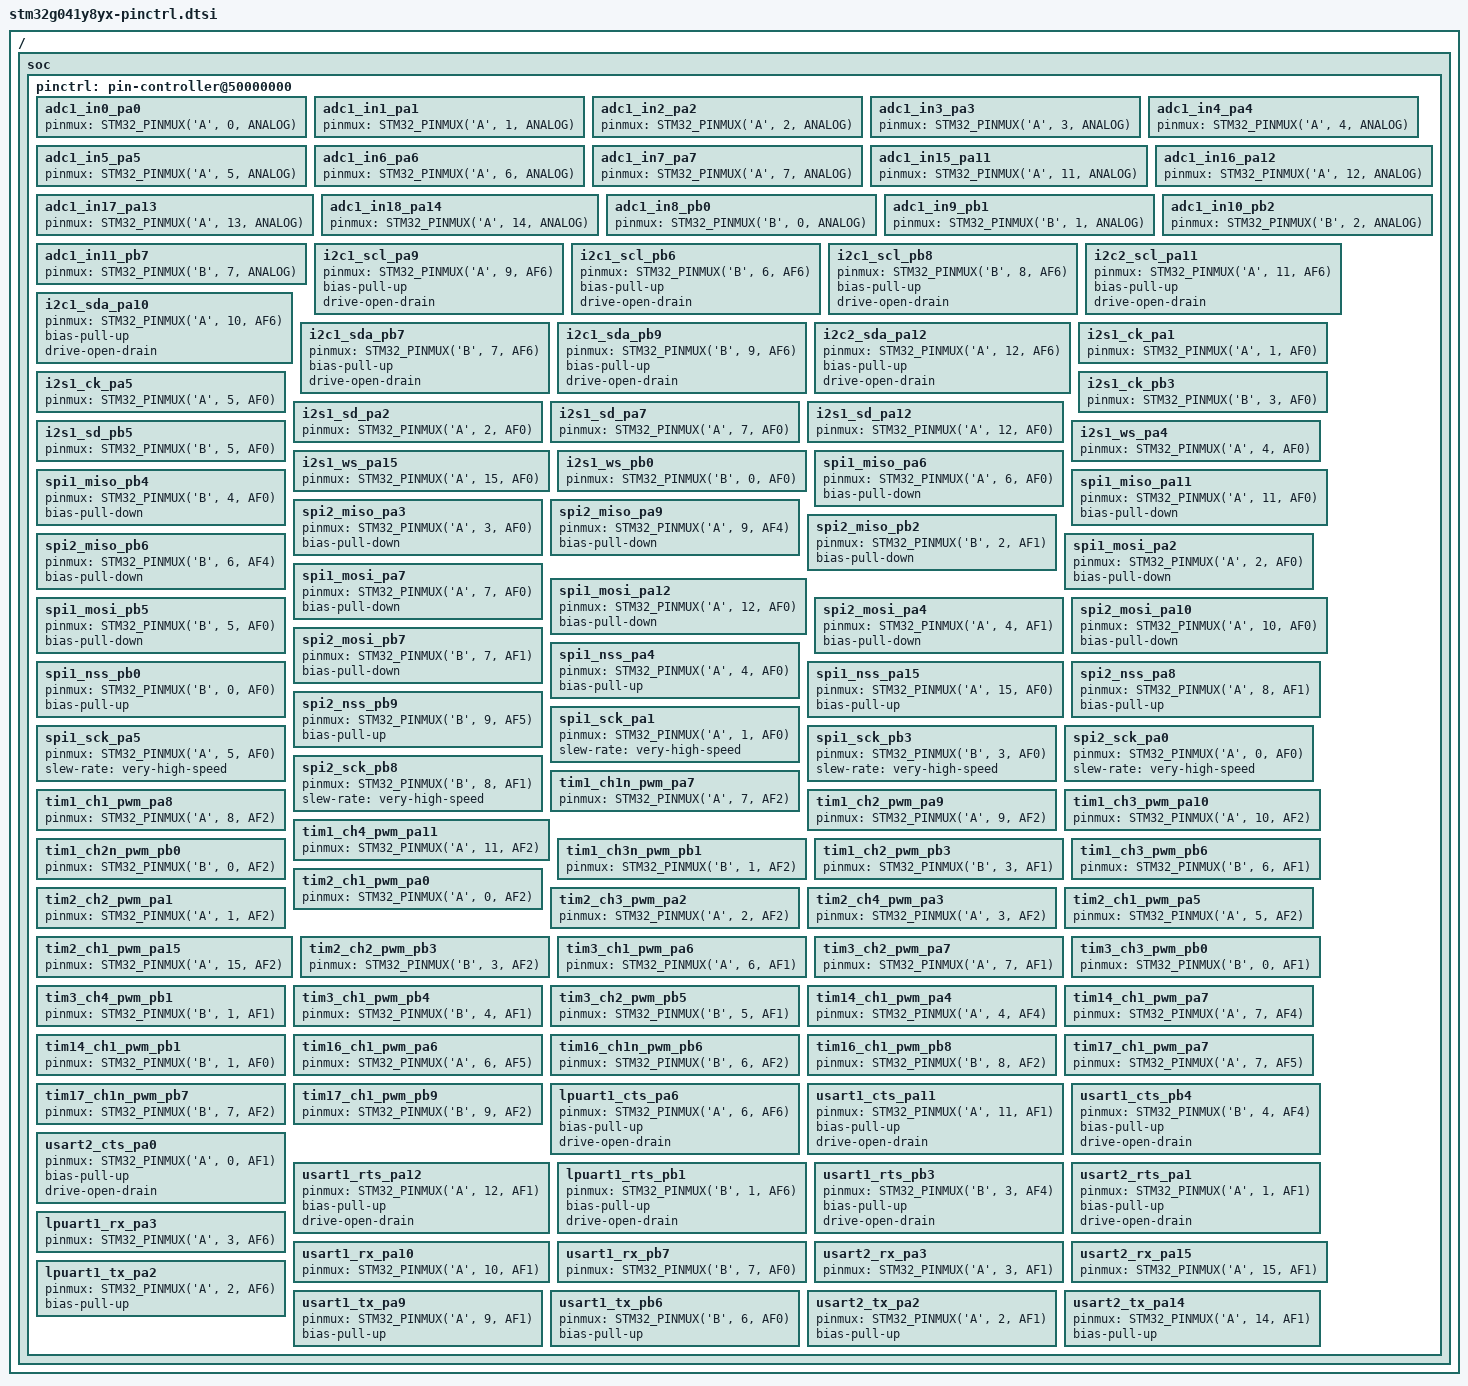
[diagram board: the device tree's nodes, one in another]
/*
 * NOTE: Autogenerated file using genpinctrl.py
 *
 * SPDX-License-Identifier: Apache-2.0
 */

#include <dt-bindings/pinctrl/stm32-pinctrl.h>

/ {
	soc {
		pinctrl: pin-controller@50000000 {

			/* ADC_IN / ADC_INN / ADC_INP */

			adc1_in0_pa0: adc1_in0_pa0 {
				pinmux = <STM32_PINMUX('A', 0, ANALOG)>;
			};

			adc1_in1_pa1: adc1_in1_pa1 {
				pinmux = <STM32_PINMUX('A', 1, ANALOG)>;
			};

			adc1_in2_pa2: adc1_in2_pa2 {
				pinmux = <STM32_PINMUX('A', 2, ANALOG)>;
			};

			adc1_in3_pa3: adc1_in3_pa3 {
				pinmux = <STM32_PINMUX('A', 3, ANALOG)>;
			};

			adc1_in4_pa4: adc1_in4_pa4 {
				pinmux = <STM32_PINMUX('A', 4, ANALOG)>;
			};

			adc1_in5_pa5: adc1_in5_pa5 {
				pinmux = <STM32_PINMUX('A', 5, ANALOG)>;
			};

			adc1_in6_pa6: adc1_in6_pa6 {
				pinmux = <STM32_PINMUX('A', 6, ANALOG)>;
			};

			adc1_in7_pa7: adc1_in7_pa7 {
				pinmux = <STM32_PINMUX('A', 7, ANALOG)>;
			};

			adc1_in15_pa11: adc1_in15_pa11 {
				pinmux = <STM32_PINMUX('A', 11, ANALOG)>;
			};

			adc1_in16_pa12: adc1_in16_pa12 {
				pinmux = <STM32_PINMUX('A', 12, ANALOG)>;
			};

			adc1_in17_pa13: adc1_in17_pa13 {
				pinmux = <STM32_PINMUX('A', 13, ANALOG)>;
			};

			adc1_in18_pa14: adc1_in18_pa14 {
				pinmux = <STM32_PINMUX('A', 14, ANALOG)>;
			};

			adc1_in8_pb0: adc1_in8_pb0 {
				pinmux = <STM32_PINMUX('B', 0, ANALOG)>;
			};

			adc1_in9_pb1: adc1_in9_pb1 {
				pinmux = <STM32_PINMUX('B', 1, ANALOG)>;
			};

			adc1_in10_pb2: adc1_in10_pb2 {
				pinmux = <STM32_PINMUX('B', 2, ANALOG)>;
			};

			adc1_in11_pb7: adc1_in11_pb7 {
				pinmux = <STM32_PINMUX('B', 7, ANALOG)>;
			};

			/* I2C_SCL */

			i2c1_scl_pa9: i2c1_scl_pa9 {
				pinmux = <STM32_PINMUX('A', 9, AF6)>;
				bias-pull-up;
				drive-open-drain;
			};

			i2c1_scl_pb6: i2c1_scl_pb6 {
				pinmux = <STM32_PINMUX('B', 6, AF6)>;
				bias-pull-up;
				drive-open-drain;
			};

			i2c1_scl_pb8: i2c1_scl_pb8 {
				pinmux = <STM32_PINMUX('B', 8, AF6)>;
				bias-pull-up;
				drive-open-drain;
			};

			i2c2_scl_pa11: i2c2_scl_pa11 {
				pinmux = <STM32_PINMUX('A', 11, AF6)>;
				bias-pull-up;
				drive-open-drain;
			};

			/* I2C_SDA */

			i2c1_sda_pa10: i2c1_sda_pa10 {
				pinmux = <STM32_PINMUX('A', 10, AF6)>;
				bias-pull-up;
				drive-open-drain;
			};

			i2c1_sda_pb7: i2c1_sda_pb7 {
				pinmux = <STM32_PINMUX('B', 7, AF6)>;
				bias-pull-up;
				drive-open-drain;
			};

			i2c1_sda_pb9: i2c1_sda_pb9 {
				pinmux = <STM32_PINMUX('B', 9, AF6)>;
				bias-pull-up;
				drive-open-drain;
			};

			i2c2_sda_pa12: i2c2_sda_pa12 {
				pinmux = <STM32_PINMUX('A', 12, AF6)>;
				bias-pull-up;
				drive-open-drain;
			};

			/* I2S_CK */

			i2s1_ck_pa1: i2s1_ck_pa1 {
				pinmux = <STM32_PINMUX('A', 1, AF0)>;
			};

			i2s1_ck_pa5: i2s1_ck_pa5 {
				pinmux = <STM32_PINMUX('A', 5, AF0)>;
			};

			i2s1_ck_pb3: i2s1_ck_pb3 {
				pinmux = <STM32_PINMUX('B', 3, AF0)>;
			};

			/* I2S_SD */

			i2s1_sd_pa2: i2s1_sd_pa2 {
				pinmux = <STM32_PINMUX('A', 2, AF0)>;
			};

			i2s1_sd_pa7: i2s1_sd_pa7 {
				pinmux = <STM32_PINMUX('A', 7, AF0)>;
			};

			i2s1_sd_pa12: i2s1_sd_pa12 {
				pinmux = <STM32_PINMUX('A', 12, AF0)>;
			};

			i2s1_sd_pb5: i2s1_sd_pb5 {
				pinmux = <STM32_PINMUX('B', 5, AF0)>;
			};

			/* I2S_WS */

			i2s1_ws_pa4: i2s1_ws_pa4 {
				pinmux = <STM32_PINMUX('A', 4, AF0)>;
			};

			i2s1_ws_pa15: i2s1_ws_pa15 {
				pinmux = <STM32_PINMUX('A', 15, AF0)>;
			};

			i2s1_ws_pb0: i2s1_ws_pb0 {
				pinmux = <STM32_PINMUX('B', 0, AF0)>;
			};

			/* SPI_MISO */

			spi1_miso_pa6: spi1_miso_pa6 {
				pinmux = <STM32_PINMUX('A', 6, AF0)>;
				bias-pull-down;
			};

			spi1_miso_pa11: spi1_miso_pa11 {
				pinmux = <STM32_PINMUX('A', 11, AF0)>;
				bias-pull-down;
			};

			spi1_miso_pb4: spi1_miso_pb4 {
				pinmux = <STM32_PINMUX('B', 4, AF0)>;
				bias-pull-down;
			};

			spi2_miso_pa3: spi2_miso_pa3 {
				pinmux = <STM32_PINMUX('A', 3, AF0)>;
				bias-pull-down;
			};

			spi2_miso_pa9: spi2_miso_pa9 {
				pinmux = <STM32_PINMUX('A', 9, AF4)>;
				bias-pull-down;
			};

			spi2_miso_pb2: spi2_miso_pb2 {
				pinmux = <STM32_PINMUX('B', 2, AF1)>;
				bias-pull-down;
			};

			spi2_miso_pb6: spi2_miso_pb6 {
				pinmux = <STM32_PINMUX('B', 6, AF4)>;
				bias-pull-down;
			};

			/* SPI_MOSI */

			spi1_mosi_pa2: spi1_mosi_pa2 {
				pinmux = <STM32_PINMUX('A', 2, AF0)>;
				bias-pull-down;
			};

			spi1_mosi_pa7: spi1_mosi_pa7 {
				pinmux = <STM32_PINMUX('A', 7, AF0)>;
				bias-pull-down;
			};

			spi1_mosi_pa12: spi1_mosi_pa12 {
				pinmux = <STM32_PINMUX('A', 12, AF0)>;
				bias-pull-down;
			};

			spi1_mosi_pb5: spi1_mosi_pb5 {
				pinmux = <STM32_PINMUX('B', 5, AF0)>;
				bias-pull-down;
			};

			spi2_mosi_pa4: spi2_mosi_pa4 {
				pinmux = <STM32_PINMUX('A', 4, AF1)>;
				bias-pull-down;
			};

			spi2_mosi_pa10: spi2_mosi_pa10 {
				pinmux = <STM32_PINMUX('A', 10, AF0)>;
				bias-pull-down;
			};

			spi2_mosi_pb7: spi2_mosi_pb7 {
				pinmux = <STM32_PINMUX('B', 7, AF1)>;
				bias-pull-down;
			};

			/* SPI_NSS */

			spi1_nss_pa4: spi1_nss_pa4 {
				pinmux = <STM32_PINMUX('A', 4, AF0)>;
				bias-pull-up;
			};

			spi1_nss_pa15: spi1_nss_pa15 {
				pinmux = <STM32_PINMUX('A', 15, AF0)>;
				bias-pull-up;
			};

			spi1_nss_pb0: spi1_nss_pb0 {
				pinmux = <STM32_PINMUX('B', 0, AF0)>;
				bias-pull-up;
			};

			spi2_nss_pa8: spi2_nss_pa8 {
				pinmux = <STM32_PINMUX('A', 8, AF1)>;
				bias-pull-up;
			};

			spi2_nss_pb9: spi2_nss_pb9 {
				pinmux = <STM32_PINMUX('B', 9, AF5)>;
				bias-pull-up;
			};

			/* SPI_SCK */

			spi1_sck_pa1: spi1_sck_pa1 {
				pinmux = <STM32_PINMUX('A', 1, AF0)>;
				slew-rate = "very-high-speed";
			};

			spi1_sck_pa5: spi1_sck_pa5 {
				pinmux = <STM32_PINMUX('A', 5, AF0)>;
				slew-rate = "very-high-speed";
			};

			spi1_sck_pb3: spi1_sck_pb3 {
				pinmux = <STM32_PINMUX('B', 3, AF0)>;
				slew-rate = "very-high-speed";
			};

			spi2_sck_pa0: spi2_sck_pa0 {
				pinmux = <STM32_PINMUX('A', 0, AF0)>;
				slew-rate = "very-high-speed";
			};

			spi2_sck_pb8: spi2_sck_pb8 {
				pinmux = <STM32_PINMUX('B', 8, AF1)>;
				slew-rate = "very-high-speed";
			};

			/* TIM_CH_PWM / TIM_CHN_PWM */

			tim1_ch1n_pwm_pa7: tim1_ch1n_pwm_pa7 {
				pinmux = <STM32_PINMUX('A', 7, AF2)>;
			};

			tim1_ch1_pwm_pa8: tim1_ch1_pwm_pa8 {
				pinmux = <STM32_PINMUX('A', 8, AF2)>;
			};

			tim1_ch2_pwm_pa9: tim1_ch2_pwm_pa9 {
				pinmux = <STM32_PINMUX('A', 9, AF2)>;
			};

			tim1_ch3_pwm_pa10: tim1_ch3_pwm_pa10 {
				pinmux = <STM32_PINMUX('A', 10, AF2)>;
			};

			tim1_ch4_pwm_pa11: tim1_ch4_pwm_pa11 {
				pinmux = <STM32_PINMUX('A', 11, AF2)>;
			};

			tim1_ch2n_pwm_pb0: tim1_ch2n_pwm_pb0 {
				pinmux = <STM32_PINMUX('B', 0, AF2)>;
			};

			tim1_ch3n_pwm_pb1: tim1_ch3n_pwm_pb1 {
				pinmux = <STM32_PINMUX('B', 1, AF2)>;
			};

			tim1_ch2_pwm_pb3: tim1_ch2_pwm_pb3 {
				pinmux = <STM32_PINMUX('B', 3, AF1)>;
			};

			tim1_ch3_pwm_pb6: tim1_ch3_pwm_pb6 {
				pinmux = <STM32_PINMUX('B', 6, AF1)>;
			};

			tim2_ch1_pwm_pa0: tim2_ch1_pwm_pa0 {
				pinmux = <STM32_PINMUX('A', 0, AF2)>;
			};

			tim2_ch2_pwm_pa1: tim2_ch2_pwm_pa1 {
				pinmux = <STM32_PINMUX('A', 1, AF2)>;
			};

			tim2_ch3_pwm_pa2: tim2_ch3_pwm_pa2 {
				pinmux = <STM32_PINMUX('A', 2, AF2)>;
			};

			tim2_ch4_pwm_pa3: tim2_ch4_pwm_pa3 {
				pinmux = <STM32_PINMUX('A', 3, AF2)>;
			};

			tim2_ch1_pwm_pa5: tim2_ch1_pwm_pa5 {
				pinmux = <STM32_PINMUX('A', 5, AF2)>;
			};

			tim2_ch1_pwm_pa15: tim2_ch1_pwm_pa15 {
				pinmux = <STM32_PINMUX('A', 15, AF2)>;
			};

			tim2_ch2_pwm_pb3: tim2_ch2_pwm_pb3 {
				pinmux = <STM32_PINMUX('B', 3, AF2)>;
			};

			tim3_ch1_pwm_pa6: tim3_ch1_pwm_pa6 {
				pinmux = <STM32_PINMUX('A', 6, AF1)>;
			};

			tim3_ch2_pwm_pa7: tim3_ch2_pwm_pa7 {
				pinmux = <STM32_PINMUX('A', 7, AF1)>;
			};

			tim3_ch3_pwm_pb0: tim3_ch3_pwm_pb0 {
				pinmux = <STM32_PINMUX('B', 0, AF1)>;
			};

			tim3_ch4_pwm_pb1: tim3_ch4_pwm_pb1 {
				pinmux = <STM32_PINMUX('B', 1, AF1)>;
			};

			tim3_ch1_pwm_pb4: tim3_ch1_pwm_pb4 {
				pinmux = <STM32_PINMUX('B', 4, AF1)>;
			};

			tim3_ch2_pwm_pb5: tim3_ch2_pwm_pb5 {
				pinmux = <STM32_PINMUX('B', 5, AF1)>;
			};

			tim14_ch1_pwm_pa4: tim14_ch1_pwm_pa4 {
				pinmux = <STM32_PINMUX('A', 4, AF4)>;
			};

			tim14_ch1_pwm_pa7: tim14_ch1_pwm_pa7 {
				pinmux = <STM32_PINMUX('A', 7, AF4)>;
			};

			tim14_ch1_pwm_pb1: tim14_ch1_pwm_pb1 {
				pinmux = <STM32_PINMUX('B', 1, AF0)>;
			};

			tim16_ch1_pwm_pa6: tim16_ch1_pwm_pa6 {
				pinmux = <STM32_PINMUX('A', 6, AF5)>;
			};

			tim16_ch1n_pwm_pb6: tim16_ch1n_pwm_pb6 {
				pinmux = <STM32_PINMUX('B', 6, AF2)>;
			};

			tim16_ch1_pwm_pb8: tim16_ch1_pwm_pb8 {
				pinmux = <STM32_PINMUX('B', 8, AF2)>;
			};

			tim17_ch1_pwm_pa7: tim17_ch1_pwm_pa7 {
				pinmux = <STM32_PINMUX('A', 7, AF5)>;
			};

			tim17_ch1n_pwm_pb7: tim17_ch1n_pwm_pb7 {
				pinmux = <STM32_PINMUX('B', 7, AF2)>;
			};

			tim17_ch1_pwm_pb9: tim17_ch1_pwm_pb9 {
				pinmux = <STM32_PINMUX('B', 9, AF2)>;
			};

			/* UART_CTS / USART_CTS / LPUART_CTS */

			lpuart1_cts_pa6: lpuart1_cts_pa6 {
				pinmux = <STM32_PINMUX('A', 6, AF6)>;
				bias-pull-up;
				drive-open-drain;
			};

			usart1_cts_pa11: usart1_cts_pa11 {
				pinmux = <STM32_PINMUX('A', 11, AF1)>;
				bias-pull-up;
				drive-open-drain;
			};

			usart1_cts_pb4: usart1_cts_pb4 {
				pinmux = <STM32_PINMUX('B', 4, AF4)>;
				bias-pull-up;
				drive-open-drain;
			};

			usart2_cts_pa0: usart2_cts_pa0 {
				pinmux = <STM32_PINMUX('A', 0, AF1)>;
				bias-pull-up;
				drive-open-drain;
			};

			/* UART_RTS / USART_RTS / LPUART_RTS */

			usart1_rts_pa12: usart1_rts_pa12 {
				pinmux = <STM32_PINMUX('A', 12, AF1)>;
				bias-pull-up;
				drive-open-drain;
			};

			lpuart1_rts_pb1: lpuart1_rts_pb1 {
				pinmux = <STM32_PINMUX('B', 1, AF6)>;
				bias-pull-up;
				drive-open-drain;
			};

			usart1_rts_pb3: usart1_rts_pb3 {
				pinmux = <STM32_PINMUX('B', 3, AF4)>;
				bias-pull-up;
				drive-open-drain;
			};

			usart2_rts_pa1: usart2_rts_pa1 {
				pinmux = <STM32_PINMUX('A', 1, AF1)>;
				bias-pull-up;
				drive-open-drain;
			};

			/* UART_RX / USART_RX / LPUART_RX */

			lpuart1_rx_pa3: lpuart1_rx_pa3 {
				pinmux = <STM32_PINMUX('A', 3, AF6)>;
			};

			usart1_rx_pa10: usart1_rx_pa10 {
				pinmux = <STM32_PINMUX('A', 10, AF1)>;
			};

			usart1_rx_pb7: usart1_rx_pb7 {
				pinmux = <STM32_PINMUX('B', 7, AF0)>;
			};

			usart2_rx_pa3: usart2_rx_pa3 {
				pinmux = <STM32_PINMUX('A', 3, AF1)>;
			};

			usart2_rx_pa15: usart2_rx_pa15 {
				pinmux = <STM32_PINMUX('A', 15, AF1)>;
			};

			/* UART_TX / USART_TX / LPUART_TX */

			lpuart1_tx_pa2: lpuart1_tx_pa2 {
				pinmux = <STM32_PINMUX('A', 2, AF6)>;
				bias-pull-up;
			};

			usart1_tx_pa9: usart1_tx_pa9 {
				pinmux = <STM32_PINMUX('A', 9, AF1)>;
				bias-pull-up;
			};

			usart1_tx_pb6: usart1_tx_pb6 {
				pinmux = <STM32_PINMUX('B', 6, AF0)>;
				bias-pull-up;
			};

			usart2_tx_pa2: usart2_tx_pa2 {
				pinmux = <STM32_PINMUX('A', 2, AF1)>;
				bias-pull-up;
			};

			usart2_tx_pa14: usart2_tx_pa14 {
				pinmux = <STM32_PINMUX('A', 14, AF1)>;
				bias-pull-up;
			};

		};
	};
};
